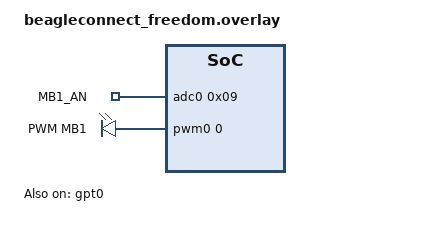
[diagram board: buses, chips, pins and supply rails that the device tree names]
/*
 * SPDX-License-Identifier: Apache-2.0
 *
 * Copyright (c) 2024 Ayush Singh <ayush@beagleboard.org>
 */

/ {
	zephyr,user {
		/* Reading mulitple pins not possible */
		io-channels = <&adc0 0x09>;
		io-channel-names = "MB1_AN";

		/*
		 * io-channels = <&adc0 0x0a>;
		 * io-channel-names = "MB2_AN";
		 */
	};

	aliases {
		pwm-led0 = &pwm_led0;
	};
	pwmleds {
		compatible = "pwm-leds";
		pwm_led0: pwm_led_0 {
			pwms = <&pwm0 0 255 PWM_POLARITY_NORMAL>;
			label = "PWM MB1";
		};
	};
	
};
&pinctrl {
	pwm0_default: pwm0_default {
		pinmux = <17 IOC_PORT_MCU_PORT_EVENT1>;
		bias-disable;
		drive-strength = <8>;
	};
};
&gpt0 {
	status = "okay";
};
